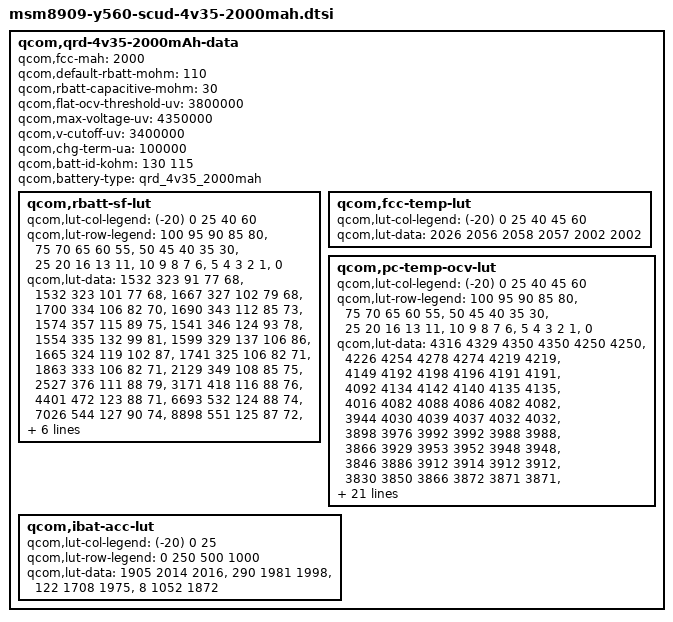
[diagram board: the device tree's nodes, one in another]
/* Copyright (c) 2013, The Linux Foundation. All rights reserved.
 *
 * This program is free software; you can redistribute it and/or modify
 * it under the terms of the GNU General Public License version 2 and
 * only version 2 as published by the Free Software Foundation.
 *
 * This program is distributed in the hope that it will be useful,
 * but WITHOUT ANY WARRANTY; without even the implied warranty of
 * MERCHANTABILITY or FITNESS FOR A PARTICULAR PURPOSE.  See the
 * GNU General Public License for more details.
 */
/* xiongzuan add battery information capacity and rbatt by 20150520 begin*/
qcom,qrd-4v35-2000mAh-data {
	qcom,fcc-mah = <2000>;
	qcom,default-rbatt-mohm = <110>;
	qcom,rbatt-capacitive-mohm = <30>;
	qcom,flat-ocv-threshold-uv = <3800000>;
	qcom,max-voltage-uv = <4350000>;
	qcom,v-cutoff-uv = <3400000>;
	qcom,chg-term-ua = <100000>;
	qcom,batt-id-kohm = <130 115>;
	qcom,battery-type = "qrd_4v35_2000mah";

	qcom,rbatt-sf-lut {
		qcom,lut-col-legend = <(-20) 0 25 40 60>;
		qcom,lut-row-legend = <100 95 90 85 80>,
				<75 70 65 60 55>,
				<50 45 40 35 30>,
				<25 20 16 13 11>,
				<10 9 8 7 6 >,
				<5 4 3 2 1>,
				<0>;
		qcom,lut-data = 
				<1532 323 91 77 68>,
				<1532 323 101 77 68>,
				<1667 327 102 79 68>,
				<1700 334 106 82 70>,
				<1690 343 112 85 73>,
				<1574 357 115 89 75>,
				<1541 346 124 93 78>,
				<1554 335 132 99 81>,
				<1599 329 137 106 86>,
				<1665 324 119 102 87>,
				<1741 325 106 82 71>,
				<1863 333 106 82 71>,
				<2129 349 108 85 75>,
				<2527 376 111 88 79>,
				<3171 418 116 88 76>,
				<4401 472 123 88 71>,
				<6693 532 124 88 74>,
				<7026 544 127 90 74>,
				<8898 551 125 87 72>,
				<9476 558 131 90 74>,
				<9207 560 128 93 76>,//10
				<9421 610 128 96 78>,
				<9098 597 131 101 79>,
				<9960 608 132 106 82>,
				<9541 574 127 110 81>,
				<9042 616 134 113 81>,
				<9444 618 136 109 82>,
				<9800 626 139 118 90>,
				<9301 613 229 176 104>,
				<9402 615 241 153 127>,
				<9479 888 282 150 115>;
	};

	qcom,fcc-temp-lut {
		qcom,lut-col-legend = <(-20) 0 25 40 45 60>;
		qcom,lut-data = <2026 2056 2058 2057 2002 2002>;
	};

	qcom,pc-temp-ocv-lut {
		qcom,lut-col-legend = <(-20) 0 25 40 45 60>;
		qcom,lut-row-legend = <100 95 90 85 80>,
				<75 70 65 60 55>,
				<50 45 40 35 30>,
				<25 20 16 13 11>,
				<10 9 8 7 6>,
				<5 4 3 2 1>,
				<0>;
		qcom,lut-data = 
 				<4316 4329 4350 4350 4250 4250>,//100
				<4226 4254 4278 4274 4219 4219>,
				<4149 4192 4198 4196 4191 4191>,//90
				<4092 4134 4142 4140 4135 4135>,
				<4016 4082 4088 4086 4082 4082>,//80
				<3944 4030 4039 4037 4032 4032>,
				<3898 3976 3992 3992 3988 3988>,//70
				<3866 3929 3953 3952 3948 3948>,
				<3846 3886 3912 3914 3912 3912>,//60
				<3830 3850 3866 3872 3871 3871>,
				<3814 3822 3836 3835 3828 3828>,//50
				<3798 3800 3817 3816 3806 3806>,
				<3782 3786 3800 3798 3788 3788>,//40
				<3764 3776 3786 3783 3773 3770>,
				<3744 3764 3770 3765 3756 3746>,//30
				<3720 3748 3756 3748 3734 3729>,
				<3688 3723 3734 3726 3712 3712>,//20
				<3652 3700 3704 3696 3683 3683>,
				<3612 3684 3676 3668 3657 3657>,//13
				<3576 3674 3669 3664 3652 3652>,
				<3552 3670 3666 3660 3650 3652>,//10
				<3524 3664 3663 3658 3648 3648>,
				<3490 3659 3659 3654 3644 3648>,
				<3452 3651 3654 3649 3638 3638>,
				<3403 3638 3645 3638 3626 3626>,
				<3343 3612 3618 3610 3590 3590>,
				<3263 3570 3570 3559 3540 3540>,
				<3189 3509 3505 3494 3474 3474>,
				<3126 3422 3417 3405 3385 3385>,
				<3058 3391 3386 3373 3354 3354>,
				<3000 3300 3300 3300 3300 3300>;
	};
	qcom,ibat-acc-lut {
		qcom,lut-col-legend = <(-20) 0 25>;
		qcom,lut-row-legend = <0 250 500 1000>;
		qcom,lut-data = 
				<1905 2014 2016>,
				<290 1981 1998>,
				<122 1708 1975>,
				<8 1052 1872>;
	};
};
/* xiongzuan add battery information capacity and rbatt by 20150520 end*/
